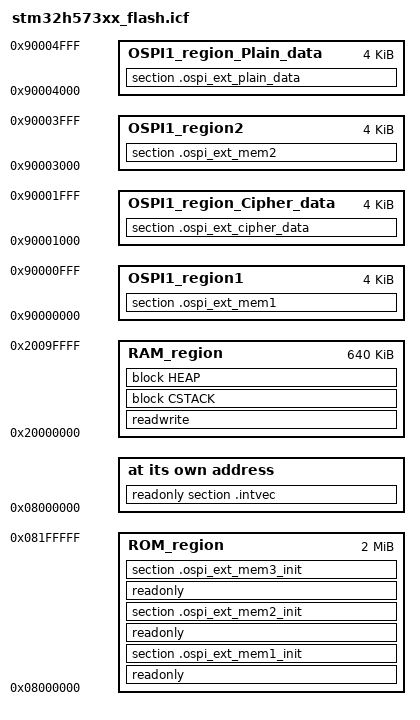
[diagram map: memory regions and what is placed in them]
/*###ICF### Section handled by ICF editor, don't touch! ****/
/*-Editor annotation file-*/
/* IcfEditorFile="$TOOLKIT_DIR$\config\ide\IcfEditor\cortex_v1_0.xml" */
/*-Specials-*/
define symbol __ICFEDIT_intvec_start__ = 0x08000000;
/*-Memory Regions-*/
define symbol __ICFEDIT_region_ROM_start__ = 0x08000000;
define symbol __ICFEDIT_region_ROM_end__   = 0x081FFFFF;
define symbol __ICFEDIT_region_RAM_start__ = 0x20000000;
define symbol __ICFEDIT_region_RAM_end__   = 0x2009FFFF;
define symbol __ICFEDIT_region1_OSPI1_start__ = 0x90000000;
define symbol __ICFEDIT_region1_OSPI1_end__   = 0x90000FFF;
define symbol __ICFEDIT_region2_OSPI1_start__ = 0x90001000;
define symbol __ICFEDIT_region2_OSPI1_end__   = 0x90001FFF;
define symbol __ICFEDIT_region3_OSPI1_start__ = 0x90003000;
define symbol __ICFEDIT_region3_OSPI1_end__   = 0x90003FFF;
define symbol __ICFEDIT_region4_OSPI1_start__ = 0x90004000;
define symbol __ICFEDIT_region4_OSPI1_end__   = 0x90004FFF;


/*-Sizes-*/
define symbol __ICFEDIT_size_cstack__ = 0x12000;
define symbol __ICFEDIT_size_heap__   = 0x1000;
/**** End of ICF editor section. ###ICF###*/

define memory mem with size = 4G;
define region ROM_region              = mem:[from __ICFEDIT_region_ROM_start__   to __ICFEDIT_region_ROM_end__];
define region RAM_region              = mem:[from __ICFEDIT_region_RAM_start__   to __ICFEDIT_region_RAM_end__];
define region OSPI1_region1           = mem:[from __ICFEDIT_region1_OSPI1_start__ to __ICFEDIT_region1_OSPI1_end__];
define region OSPI1_region2           = mem:[from __ICFEDIT_region3_OSPI1_start__ to __ICFEDIT_region3_OSPI1_end__];
define region OSPI1_region_Cipher_data           = mem:[from __ICFEDIT_region2_OSPI1_start__ to __ICFEDIT_region2_OSPI1_end__];
define region OSPI1_region_Plain_data            = mem:[from __ICFEDIT_region4_OSPI1_start__ to __ICFEDIT_region4_OSPI1_end__];

define block CSTACK    with alignment = 8, size = __ICFEDIT_size_cstack__   { };
define block HEAP      with alignment = 8, size = __ICFEDIT_size_heap__     { };

initialize by copy { readwrite };
do not initialize  { section .noinit };
initialize manually { section .ospi_ext_mem1};
initialize manually { section .ospi_ext_mem2};
initialize manually { section .ospi_ext_cipher_data};
initialize manually { section .ospi_ext_Plain_data};

place at address mem:__ICFEDIT_intvec_start__ { readonly section .intvec };

place in ROM_region    { readonly, section .ospi_ext_mem1_init};
place in ROM_region    { readonly, section .ospi_ext_mem2_init};
place in ROM_region    { readonly, section .ospi_ext_mem3_init};
place in RAM_region    { readwrite, 
                        block CSTACK, block HEAP };
place in OSPI1_region1  { section .ospi_ext_mem1};
place in OSPI1_region2  { section .ospi_ext_mem2};
place in OSPI1_region_Cipher_data  { section .ospi_ext_cipher_data};
place in OSPI1_region_Plain_data  { section .ospi_ext_plain_data};
         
